AUTOSAR XML (schema 00049)
standard types defined: boolean, float32, sint16, uint8, boolean_CompuMethod, boolean_DataConstr, float32_DataConstr, sint16_DataConstr, uint8_DataConstr
package /ComponentTypes
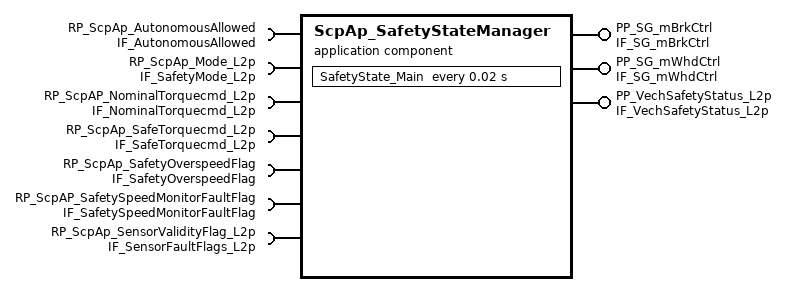
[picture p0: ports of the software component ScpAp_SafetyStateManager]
  application sw component type ScpAp_SafetyStateManager
    provide port PP_SG_mBrkCtrl: nonqueued-sender-com-spec{data-element=SG_mBrkCtrl_VDP, handle-out-of-range=DEFAULT, init-value=fields=[Aeb_Active_Ebcm:0, BrkEnbl_EBCM2L:0, BrkTrqRq:0, ClearFltRq_Ebcm:0, DsblTCS:0, EbcmMaintModeRq:0, EbcmShtdwnRq:0, EpbCalCmd:0, EPBCmd:0, HoldRq:0, MsgCntr_mBrkCtrl:0, MsgCrc_mBrkCtrl:0]}, provided-interface=IF_SG_mBrkCtrl
    provide port PP_SG_mWhdCtrl: nonqueued-sender-com-spec{data-element=SG_mWhdCtrl_VDP, init-value=fields=[Boot:0, CtrlMode_Whd:0, Debug:0, EnblCmd:0, MsgCntr_mWhdCtrl:0, MsgCrc_mWhdCtrl:0, MtrMode:0, SpdCmd:0, SpdSlewLmt:0, TrqCmd:0, TrqSlewLmt:0]}, provided-interface=IF_SG_mWhdCtrl
    provide port PP_VechSafetyStatus_L2p: nonqueued-sender-com-spec=data-element=IF_VechSafetyStatus_L2p, provided-interface=IF_VechSafetyStatus_L2p
    7 x require port:
      RP_ScpAp_AutonomousAllowed: nonqueued-receiver-com-spec{data-element=IF_AutonomousAllowed, filter=data-filter-type=ALWAYS}, required-interface=IF_AutonomousAllowed
      RP_ScpAp_Mode_L2p: nonqueued-receiver-com-spec{data-element=IF_SafetyMode_L2p, filter=data-filter-type=ALWAYS}, required-interface=IF_SafetyMode_L2p
      RP_ScpAP_NominalTorquecmd_L2p: nonqueued-receiver-com-spec{data-element=IF_NominalTorquecmd_L2p, filter=data-filter-type=ALWAYS}, required-interface=IF_NominalTorquecmd_L2p
      RP_ScpAp_SafeTorquecmd_L2p: nonqueued-receiver-com-spec{data-element=IF_SafeTorquecmd_L2p, filter=data-filter-type=ALWAYS}, required-interface=IF_SafeTorquecmd_L2p
      RP_ScpAp_SafetyOverspeedFlag: nonqueued-receiver-com-spec{data-element=IF_SafetyOverspeedFlag, filter=data-filter-type=ALWAYS, init-value=0}, required-interface=IF_SafetyOverspeedFlag
      RP_ScpAP_SafetySpeedMonitorFaultFlag: nonqueued-receiver-com-spec{data-element=IF_SafetySpeedMonitorFaultFlag, filter=data-filter-type=ALWAYS, init-value=0}, required-interface=IF_SafetySpeedMonitorFaultFlag
      RP_ScpAp_SensorValidityFlag_L2p: nonqueued-receiver-com-spec{data-element=IF_SensorFaultFlags_L2p, filter=data-filter-type=ALWAYS, init-value=fields=[MotorRPM_Fault:0, Accel_Fault:0, WSS_Fault:0, VechSpeedEst_Fault:0]}, required-interface=IF_SensorFaultFlags_L2p
    behavior ScpAp_SafetyStateManager_InternalBehavior: handle-termination-and-restart=NO-SUPPORT
      timing event TMT_SafetyState_Main: start-on-event=SafetyState_Main, period=0.02
      runnable SafetyState_Main
        data-receive-point-by-arguments:
          7 x access:
            REC_RP_ScpAp_AutonomousAllowed_IF_AutonomousAllowed: accessed-variable=RP_ScpAp_AutonomousAllowed.IF_AutonomousAllowed
            REC_RP_ScpAp_Mode_L2p_IF_SafetyMode_L2p: accessed-variable=RP_ScpAp_Mode_L2p.IF_SafetyMode_L2p
            REC_RP_ScpAP_NominalTorquecmd_L2p_IF_NominalTorquecmd_L2p: accessed-variable=RP_ScpAP_NominalTorquecmd_L2p.IF_NominalTorquecmd_L2p
            REC_RP_ScpAp_SafeTorquecmd_L2p_IF_SafeTorquecmd_L2p: accessed-variable=RP_ScpAp_SafeTorquecmd_L2p.IF_SafeTorquecmd_L2p
            REC_RP_ScpAp_SafetyOverspeedFlag_IF_SafetyOverspeedFlag: accessed-variable=RP_ScpAp_SafetyOverspeedFlag.IF_SafetyOverspeedFlag
            REC_RP_ScpAP_SafetySpeedMonitorFaultFlag_IF_SafetySpeedMonitorFaultFlag: accessed-variable=RP_ScpAP_SafetySpeedMonitorFaultFlag.IF_SafetySpeedMonitorFaultFlag
            REC_RP_ScpAp_SensorValidityFlag_L2p_IF_SensorFaultFlags_L2p: accessed-variable=RP_ScpAp_SensorValidityFlag_L2p.IF_SensorFaultFlags_L2p
        data-send-points:
          access SEND_PP_SG_mBrkCtrl_SG_mBrkCtrl_VDP: accessed-variable=PP_SG_mBrkCtrl.SG_mBrkCtrl_VDP
          access SEND_PP_SG_mWhdCtrl_SG_mWhdCtrl_VDP: accessed-variable=PP_SG_mWhdCtrl.SG_mWhdCtrl_VDP
          access SEND_PP_VechSafetyStatus_L2p_IF_VechSafetyStatus_L2p: accessed-variable=PP_VechSafetyStatus_L2p.IF_VechSafetyStatus_L2p
  swc implementation ScpAp_SafetyStateManager_Implementation: behavior=ScpAp_SafetyStateManager_InternalBehavior
    code-descriptors:
      code Default: artifact-descriptors=autosar-engineering-object={short-label=Default, category=SWSRC}
package /DataTypes
  5 x impl type:
    IF_SensorFaultFlgs_L2p_IDT: category=STRUCTURE, sw-calibration-access=READ-ONLY, type-emitter=RTE
      4 x element, all with category=VALUE, base-type=boolean, sw-calibration-access=READ-ONLY:
        MotorRPM_Fault
        Accel_Fault
        WSS_Fault
        VechSpeedEst_Fault
    SafetyMode_L2p_IDT: category=VALUE, base-type=BaseTypes/uint8, sw-calibration-access=READ-ONLY, compu {0=MANUAL (CompuScale), 1=AUTONOMOUS (CompuScale), 3=TELEOPS (CompuScale)}, type-emitter=RTE
    SG_mBrkCtrl_IDT: category=STRUCTURE
      12 x element, all with category=TYPE_REFERENCE:
        Aeb_Active_Ebcm: range raw 0..1, implementation-data-type=boolean
        BrkEnbl_EBCM2L: range raw 0..1, implementation-data-type=boolean
        BrkTrqRq: range raw 0..65535, implementation-data-type=float32
        ClearFltRq_Ebcm: range raw 0..1, implementation-data-type=boolean
        DsblTCS: range raw 0..1, implementation-data-type=boolean
        EbcmMaintModeRq: range raw 0..1, implementation-data-type=boolean
        EbcmShtdwnRq: range raw 0..1, implementation-data-type=boolean
        EpbCalCmd: range raw 0..1, implementation-data-type=boolean
        EPBCmd: range raw 0..3, implementation-data-type=uint8
        HoldRq: range raw 0..1, implementation-data-type=boolean
        MsgCntr_mBrkCtrl: range raw 0..15, implementation-data-type=uint8
        MsgCrc_mBrkCtrl: range raw 0..255, implementation-data-type=uint8
    SG_mWhdCtrl_IDT: category=STRUCTURE
      11 x element, all with category=TYPE_REFERENCE:
        Boot: range raw 0..1, implementation-data-type=boolean
        CtrlMode_Whd: range raw 0..3, implementation-data-type=uint8
        Debug: range raw 0..1, implementation-data-type=boolean
        EnblCmd: range raw 0..1, implementation-data-type=boolean
        MsgCntr_mWhdCtrl: range raw 0..15, implementation-data-type=uint8
        MsgCrc_mWhdCtrl: range raw 0..255, implementation-data-type=uint8
        MtrMode: range raw 0..7, implementation-data-type=uint8
        SpdCmd: range raw -2048..2046, implementation-data-type=float32
        SpdSlewLmt: range raw 0..255, implementation-data-type=float32
        TrqCmd: range raw -2048..2046, implementation-data-type=float32
        TrqSlewLmt: range raw 0..255, implementation-data-type=float32
    VechSafetyStatus_L2p_IDT: category=VALUE, base-type=BaseTypes/uint8, sw-calibration-access=READ-ONLY, compu {0=NORMAL (CompuScale), 1=DEGRADED (CompuScale), 2=FAULT_STOP (CompuScale), 3=OVERSPEED_HANDLING}, type-emitter=RTE
package /PortInterfaces
  10 x sender receiver interface:
    IF_AutonomousAllowed: invalidation-policy{data-element=IF_AutonomousAllowed, handle-invalid=DONT-INVALIDATE}
      data IF_AutonomousAllowed: type=boolean
    IF_NominalTorquecmd_L2p: invalidation-policy{data-element=IF_NominalTorquecmd_L2p, handle-invalid=DONT-INVALIDATE}
      data IF_NominalTorquecmd_L2p: type=sint16
    IF_SafeTorquecmd_L2p: invalidation-policy{data-element=IF_SafeTorquecmd_L2p, handle-invalid=DONT-INVALIDATE}
      data IF_SafeTorquecmd_L2p: type=sint16
    IF_SafetyMode_L2p: invalidation-policy{data-element=IF_SafetyMode_L2p, handle-invalid=DONT-INVALIDATE}
      data IF_SafetyMode_L2p: type=SafetyMode_L2p_IDT
    IF_SafetyOverspeedFlag: invalidation-policy{data-element=IF_SafetyOverspeedFlag, handle-invalid=DONT-INVALIDATE}
      data IF_SafetyOverspeedFlag: type=boolean
    IF_SafetySpeedMonitorFaultFlag: invalidation-policy{data-element=IF_SafetySpeedMonitorFaultFlag, handle-invalid=DONT-INVALIDATE}
      data IF_SafetySpeedMonitorFaultFlag: type=boolean
    IF_SensorFaultFlags_L2p: invalidation-policy{data-element=IF_SensorFaultFlags_L2p, handle-invalid=DONT-INVALIDATE}
      data IF_SensorFaultFlags_L2p: type=IF_SensorFaultFlgs_L2p_IDT
    IF_SG_mBrkCtrl: invalidation-policy{data-element=SG_mBrkCtrl_VDP, handle-invalid=DONT-INVALIDATE}
      data SG_mBrkCtrl_VDP: category=STRUCTURE, type=SG_mBrkCtrl_IDT
    IF_SG_mWhdCtrl: invalidation-policy{data-element=SG_mWhdCtrl_VDP, handle-invalid=DONT-INVALIDATE}
      data SG_mWhdCtrl_VDP: category=STRUCTURE, type=SG_mWhdCtrl_IDT
    IF_VechSafetyStatus_L2p: invalidation-policy{data-element=IF_VechSafetyStatus_L2p, handle-invalid=DONT-INVALIDATE}
      data IF_VechSafetyStatus_L2p: type=VechSafetyStatus_L2p_IDT
